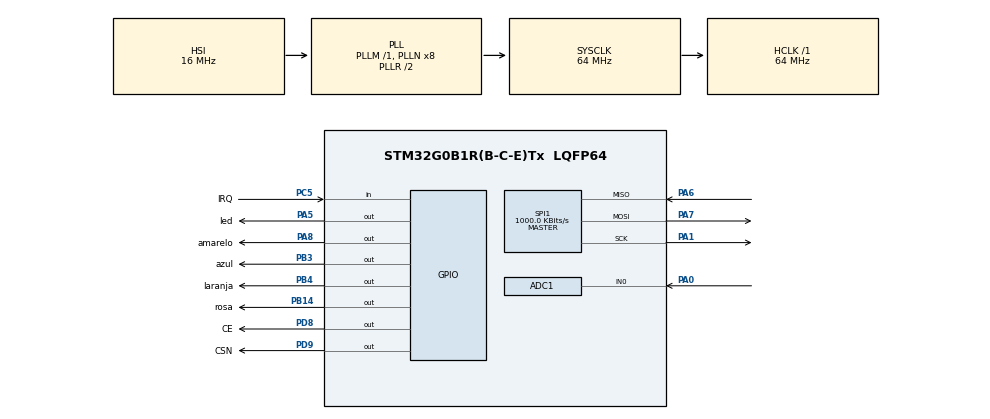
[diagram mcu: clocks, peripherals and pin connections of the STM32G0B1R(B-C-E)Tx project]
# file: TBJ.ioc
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ADC1.Channel-3\#ChannelRegularConversion=ADC_CHANNEL_0
ADC1.NbrOfConversionFlag=1
ADC1.Rank-3\#ChannelRegularConversion=1
ADC1.SamplingTime-3\#ChannelRegularConversion=ADC_SAMPLINGTIME_COMMON_1
ADC1.SamplingTimeCommon1=ADC_SAMPLETIME_79CYCLES_5
ADC1.SamplingTimeCommon2=ADC_SAMPLETIME_79CYCLES_5
ADC1.SelectedChannel=ADC_CHANNEL_0
ADC1.master=1
Mcu.Family=STM32G0
Mcu.Name=STM32G0B1R(B-C-E)Tx
Mcu.Package=LQFP64
NVIC.SPI1_IRQn=true\:0\:0\:false\:false\:true\:true\:true
NVIC.TIM16_FDCAN_IT0_IRQn=true\:0\:0\:false\:false\:true\:true\:true
NVIC.TIM1_BRK_UP_TRG_COM_IRQn=true\:0\:0\:false\:false\:true\:true\:true
NVIC.TIM1_CC_IRQn=true\:0\:0\:false\:false\:true\:true\:true
PA0.Mode=IN0
PA0.Signal=ADC1_IN0
PA1.Mode=Full_Duplex_Master
PA1.Signal=SPI1_SCK
PA13.Mode=Serial_Wire
PA13.Signal=SYS_SWDIO
PA14-BOOT0.Mode=Serial_Wire
PA14-BOOT0.Signal=SYS_SWCLK
PA5.GPIO_Label=led
PA5.GPIO_Speed=GPIO_SPEED_FREQ_VERY_HIGH
PA5.Signal=GPIO_Output
PA6.Mode=Full_Duplex_Master
PA6.Signal=SPI1_MISO
PA7.Mode=Full_Duplex_Master
PA7.Signal=SPI1_MOSI
PA8.GPIO_Label=amarelo
PA8.GPIO_Speed=GPIO_SPEED_FREQ_VERY_HIGH
PA8.Signal=GPIO_Output
PB14.GPIO_Label=rosa
PB14.GPIO_Speed=GPIO_SPEED_FREQ_VERY_HIGH
PB14.Signal=GPIO_Output
PB3.GPIO_Label=azul
PB3.GPIO_Speed=GPIO_SPEED_FREQ_VERY_HIGH
PB3.Signal=GPIO_Output
PB4.GPIO_Label=laranja
PB4.GPIO_Speed=GPIO_SPEED_FREQ_VERY_HIGH
PB4.Signal=GPIO_Output
PC5.GPIO_Label=IRQ
PC5.Signal=GPIO_Input
PD8.GPIO_Label=CE
PD8.GPIO_Speed=GPIO_SPEED_FREQ_VERY_HIGH
PD8.Signal=GPIO_Output
PD9.GPIO_Label=CSN
PD9.GPIO_Speed=GPIO_SPEED_FREQ_VERY_HIGH
PD9.Signal=GPIO_Output
ProjectManager.HeapSize=0x200
ProjectManager.StackSize=0x400
ProjectManager.TargetToolchain=STM32CubeIDE
RCC.ADCFreq_Value=64000000
RCC.AHBFreq_Value=64000000
RCC.CortexFreq_Value=64000000
RCC.EXTERNAL_CLOCK_VALUE=48000
RCC.HCLKFreq_Value=64000000
RCC.HSE_VALUE=8000000
RCC.HSI48_VALUE=48000000
RCC.HSI_VALUE=16000000
RCC.LSE_VALUE=32768
RCC.SYSCLKFreq_VALUE=64000000
RCC.SYSCLKSource=RCC_SYSCLKSOURCE_PLLCLK
RCC.USBFreq_Value=48000000
RCC.VCOOutputFreq_Value=128000000
SPI1.BaudRatePrescaler=SPI_BAUDRATEPRESCALER_64
SPI1.CalculateBaudRate=1000.0 KBits/s
SPI1.Direction=SPI_DIRECTION_2LINES
SPI1.Mode=SPI_MODE_MASTER
SPI1.VirtualType=VM_MASTER
TIM1.Period=65000
TIM1.Prescaler=63
TIM16.Period=640
TIM16.Prescaler=2000
VP_SYS_VS_DBSignals.Mode=DisableDeadBatterySignals
VP_TIM16_VS_ClockSourceINT.Mode=Enable_Timer
VP_TIM1_VS_ClockSourceINT.Mode=Internal
board=custom

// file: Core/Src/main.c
/* USER CODE BEGIN Header */
/**
  ******************************************************************************
  * @file           : main.c
  * @brief          : Main program body
  ******************************************************************************
  * @attention
  *
  * Copyright (c) 2022 STMicroelectronics.
  * All rights reserved.
  *
  * This software is licensed under terms that can be found in the LICENSE file
  * in the root directory of this software component.
  * If no LICENSE file comes with this software, it is provided AS-IS.
  *
  ******************************************************************************
  */
/* USER CODE END Header */
#include "main.h"

/* USER CODE BEGIN Includes */
#include "app.h"
#include "step.h"
/* USER CODE END Includes */

ADC_HandleTypeDef hadc1;

SPI_HandleTypeDef hspi1;

TIM_HandleTypeDef htim1;
TIM_HandleTypeDef htim16;

/* USER CODE BEGIN PV */

step_motor_t Motor;
/* USER CODE END PV */

void SystemClock_Config(void);
static void MX_GPIO_Init(void);
static void MX_SPI1_Init(void);
static void MX_TIM1_Init(void);
static void MX_ADC1_Init(void);
static void MX_TIM16_Init(void);

/* USER CODE BEGIN 0 */
//void app_init(){
//	HAL_TIM_Base_Start(&htim1);
//
//	Motor.pins.Blue.gpio = azul_GPIO_Port;
//	Motor.pins.Blue.pin = azul_Pin;
//	Motor.pins.Orange.gpio = laranja_GPIO_Port;
//	Motor.pins.Orange.pin = laranja_Pin;
//	Motor.pins.Yellow.gpio = amarelo_GPIO_Port;
//	Motor.pins.Yellow.pin = amarelo_Pin;
//	Motor.pins.Pink.gpio = rosa_GPIO_Port;
//	Motor.pins.Pink.pin = rosa_Pin;
//
//	step_init(&Motor);
//}

//void app_run(){
//	while (1){
//		step_drive_steps(&Motor, 512, STEP_DIRECTION_ACW, 8);
//		HAL_Delay(1500);
//		step_drive_steps(&Motor, 2048, STEP_DIRECTION_CW, 4);
//		HAL_Delay(800);
//    }
//
//}

//extern uint8_t data_array[4];

/* USER CODE END 0 */

int main(void)
{

  /* MCU Configuration--------------------------------------------------------*/

  /* Reset of all peripherals, Initializes the Flash interface and the Systick. */
  HAL_Init();

  /* Configure the system clock */
  SystemClock_Config();

  /* Initialize all configured peripherals */
  MX_GPIO_Init();
  MX_SPI1_Init();
  MX_TIM1_Init();
  MX_ADC1_Init();
  MX_TIM16_Init();
  /* USER CODE BEGIN 2 */

  app_init();

  app_run();

  /* USER CODE END 2 */

  /* Infinite loop */
  while (1)
  {

  }
}

void SystemClock_Config(void)
{
  RCC_OscInitTypeDef RCC_OscInitStruct = {0};
  RCC_ClkInitTypeDef RCC_ClkInitStruct = {0};

  /** Configure the main internal regulator output voltage
  */
  HAL_PWREx_ControlVoltageScaling(PWR_REGULATOR_VOLTAGE_SCALE1);
  /** Initializes the RCC Oscillators according to the specified parameters
  * in the RCC_OscInitTypeDef structure.
  */
  RCC_OscInitStruct.OscillatorType = RCC_OSCILLATORTYPE_HSI;
  RCC_OscInitStruct.HSIState = RCC_HSI_ON;
  RCC_OscInitStruct.HSIDiv = RCC_HSI_DIV1;
  RCC_OscInitStruct.HSICalibrationValue = RCC_HSICALIBRATION_DEFAULT;
  RCC_OscInitStruct.PLL.PLLState = RCC_PLL_ON;
  RCC_OscInitStruct.PLL.PLLSource = RCC_PLLSOURCE_HSI;
  RCC_OscInitStruct.PLL.PLLM = RCC_PLLM_DIV1;
  RCC_OscInitStruct.PLL.PLLN = 8;
  RCC_OscInitStruct.PLL.PLLP = RCC_PLLP_DIV2;
  RCC_OscInitStruct.PLL.PLLQ = RCC_PLLQ_DIV2;
  RCC_OscInitStruct.PLL.PLLR = RCC_PLLR_DIV2;
  if (HAL_RCC_OscConfig(&RCC_OscInitStruct) != HAL_OK)
  {
    Error_Handler();
  }
  /** Initializes the CPU, AHB and APB buses clocks
  */
  RCC_ClkInitStruct.ClockType = RCC_CLOCKTYPE_HCLK|RCC_CLOCKTYPE_SYSCLK
                              |RCC_CLOCKTYPE_PCLK1;
  RCC_ClkInitStruct.SYSCLKSource = RCC_SYSCLKSOURCE_PLLCLK;
  RCC_ClkInitStruct.AHBCLKDivider = RCC_SYSCLK_DIV1;
  RCC_ClkInitStruct.APB1CLKDivider = RCC_HCLK_DIV1;

  if (HAL_RCC_ClockConfig(&RCC_ClkInitStruct, FLASH_LATENCY_2) != HAL_OK)
  {
    Error_Handler();
  }
}

static void MX_ADC1_Init(void)
{

  ADC_ChannelConfTypeDef sConfig = {0};

  /** Configure the global features of the ADC (Clock, Resolution, Data Alignment and number of conversion)
  */
  hadc1.Instance = ADC1;
  hadc1.Init.ClockPrescaler = ADC_CLOCK_SYNC_PCLK_DIV2;
  hadc1.Init.Resolution = ADC_RESOLUTION_12B;
  hadc1.Init.DataAlign = ADC_DATAALIGN_RIGHT;
  hadc1.Init.ScanConvMode = ADC_SCAN_DISABLE;
  hadc1.Init.EOCSelection = ADC_EOC_SINGLE_CONV;
  hadc1.Init.LowPowerAutoWait = DISABLE;
  hadc1.Init.LowPowerAutoPowerOff = DISABLE;
  hadc1.Init.ContinuousConvMode = DISABLE;
  hadc1.Init.NbrOfConversion = 1;
  hadc1.Init.DiscontinuousConvMode = DISABLE;
  hadc1.Init.ExternalTrigConv = ADC_SOFTWARE_START;
  hadc1.Init.ExternalTrigConvEdge = ADC_EXTERNALTRIGCONVEDGE_NONE;
  hadc1.Init.DMAContinuousRequests = DISABLE;
  hadc1.Init.Overrun = ADC_OVR_DATA_PRESERVED;
  hadc1.Init.SamplingTimeCommon1 = ADC_SAMPLETIME_79CYCLES_5;
  hadc1.Init.SamplingTimeCommon2 = ADC_SAMPLETIME_79CYCLES_5;
  hadc1.Init.OversamplingMode = DISABLE;
  hadc1.Init.TriggerFrequencyMode = ADC_TRIGGER_FREQ_HIGH;
  if (HAL_ADC_Init(&hadc1) != HAL_OK)
  {
    Error_Handler();
  }
  /** Configure Regular Channel
  */
  sConfig.Channel = ADC_CHANNEL_0;
  sConfig.Rank = ADC_REGULAR_RANK_1;
  sConfig.SamplingTime = ADC_SAMPLINGTIME_COMMON_1;
  if (HAL_ADC_ConfigChannel(&hadc1, &sConfig) != HAL_OK)
  {
    Error_Handler();
  }

}

static void MX_SPI1_Init(void)
{

  /* SPI1 parameter configuration*/
  hspi1.Instance = SPI1;
  hspi1.Init.Mode = SPI_MODE_MASTER;
  hspi1.Init.Direction = SPI_DIRECTION_2LINES;
  hspi1.Init.DataSize = SPI_DATASIZE_8BIT;
  hspi1.Init.CLKPolarity = SPI_POLARITY_LOW;
  hspi1.Init.CLKPhase = SPI_PHASE_1EDGE;
  hspi1.Init.NSS = SPI_NSS_SOFT;
  hspi1.Init.BaudRatePrescaler = SPI_BAUDRATEPRESCALER_64;
  hspi1.Init.FirstBit = SPI_FIRSTBIT_MSB;
  hspi1.Init.TIMode = SPI_TIMODE_DISABLE;
  hspi1.Init.CRCCalculation = SPI_CRCCALCULATION_DISABLE;
  hspi1.Init.CRCPolynomial = 7;
  hspi1.Init.CRCLength = SPI_CRC_LENGTH_DATASIZE;
  hspi1.Init.NSSPMode = SPI_NSS_PULSE_ENABLE;
  if (HAL_SPI_Init(&hspi1) != HAL_OK)
  {
    Error_Handler();
  }

}

static void MX_TIM1_Init(void)
{

  TIM_ClockConfigTypeDef sClockSourceConfig = {0};
  TIM_MasterConfigTypeDef sMasterConfig = {0};

  htim1.Instance = TIM1;
  htim1.Init.Prescaler = 63;
  htim1.Init.CounterMode = TIM_COUNTERMODE_UP;
  htim1.Init.Period = 65000;
  htim1.Init.ClockDivision = TIM_CLOCKDIVISION_DIV1;
  htim1.Init.RepetitionCounter = 0;
  htim1.Init.AutoReloadPreload = TIM_AUTORELOAD_PRELOAD_DISABLE;
  if (HAL_TIM_Base_Init(&htim1) != HAL_OK)
  {
    Error_Handler();
  }
  sClockSourceConfig.ClockSource = TIM_CLOCKSOURCE_INTERNAL;
  if (HAL_TIM_ConfigClockSource(&htim1, &sClockSourceConfig) != HAL_OK)
  {
    Error_Handler();
  }
  sMasterConfig.MasterOutputTrigger = TIM_TRGO_RESET;
  sMasterConfig.MasterOutputTrigger2 = TIM_TRGO2_RESET;
  sMasterConfig.MasterSlaveMode = TIM_MASTERSLAVEMODE_DISABLE;
  if (HAL_TIMEx_MasterConfigSynchronization(&htim1, &sMasterConfig) != HAL_OK)
  {
    Error_Handler();
  }

}

static void MX_TIM16_Init(void)
{

  htim16.Instance = TIM16;
  htim16.Init.Prescaler = 2000;
  htim16.Init.CounterMode = TIM_COUNTERMODE_UP;
  htim16.Init.Period = 640;
  htim16.Init.ClockDivision = TIM_CLOCKDIVISION_DIV1;
  htim16.Init.RepetitionCounter = 0;
  htim16.Init.AutoReloadPreload = TIM_AUTORELOAD_PRELOAD_DISABLE;
  if (HAL_TIM_Base_Init(&htim16) != HAL_OK)
  {
    Error_Handler();
  }

}

static void MX_GPIO_Init(void)
{
  GPIO_InitTypeDef GPIO_InitStruct = {0};

  /* GPIO Ports Clock Enable */
  __HAL_RCC_GPIOA_CLK_ENABLE();
  __HAL_RCC_GPIOC_CLK_ENABLE();
  __HAL_RCC_GPIOB_CLK_ENABLE();
  __HAL_RCC_GPIOD_CLK_ENABLE();

  /*Configure GPIO pin Output Level */
  HAL_GPIO_WritePin(GPIOA, led_Pin|amarelo_Pin, GPIO_PIN_RESET);

  /*Configure GPIO pin Output Level */
  HAL_GPIO_WritePin(GPIOB, rosa_Pin|azul_Pin|laranja_Pin, GPIO_PIN_RESET);

  /*Configure GPIO pin Output Level */
  HAL_GPIO_WritePin(GPIOD, CE_Pin|CSN_Pin, GPIO_PIN_RESET);

  /*Configure GPIO pins : led_Pin amarelo_Pin */
  GPIO_InitStruct.Pin = led_Pin|amarelo_Pin;
  GPIO_InitStruct.Mode = GPIO_MODE_OUTPUT_PP;
  GPIO_InitStruct.Pull = GPIO_NOPULL;
  GPIO_InitStruct.Speed = GPIO_SPEED_FREQ_VERY_HIGH;
  HAL_GPIO_Init(GPIOA, &GPIO_InitStruct);

  /*Configure GPIO pin : IRQ_Pin */
  GPIO_InitStruct.Pin = IRQ_Pin;
  GPIO_InitStruct.Mode = GPIO_MODE_INPUT;
  GPIO_InitStruct.Pull = GPIO_NOPULL;
  HAL_GPIO_Init(IRQ_GPIO_Port, &GPIO_InitStruct);

  /*Configure GPIO pins : rosa_Pin azul_Pin laranja_Pin */
  GPIO_InitStruct.Pin = rosa_Pin|azul_Pin|laranja_Pin;
  GPIO_InitStruct.Mode = GPIO_MODE_OUTPUT_PP;
  GPIO_InitStruct.Pull = GPIO_NOPULL;
  GPIO_InitStruct.Speed = GPIO_SPEED_FREQ_VERY_HIGH;
  HAL_GPIO_Init(GPIOB, &GPIO_InitStruct);

  /*Configure GPIO pins : CE_Pin CSN_Pin */
  GPIO_InitStruct.Pin = CE_Pin|CSN_Pin;
  GPIO_InitStruct.Mode = GPIO_MODE_OUTPUT_PP;
  GPIO_InitStruct.Pull = GPIO_NOPULL;
  GPIO_InitStruct.Speed = GPIO_SPEED_FREQ_VERY_HIGH;
  HAL_GPIO_Init(GPIOD, &GPIO_InitStruct);

}

void Error_Handler(void)
{
  __disable_irq();
  while (1)
  {
  }
}
